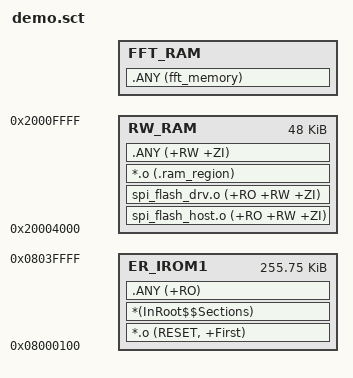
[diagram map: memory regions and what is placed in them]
; *************************************************************
; *** Scatter-Loading Description File generated by uVision ***
; *************************************************************



LR_IROM1 0x08000100 0x3FF00  {    ; load region size_region
  ER_IROM1 0x08000100 0x3FF00  {  ; load address = execution address
   *.o (RESET, +First)
   *(InRoot$$Sections)
   .ANY (+RO)
  }

  RW_RAM 0x20004000 0xc000{
    spi_flash_host.o (+RO +RW +ZI)
    spi_flash_drv.o  (+RO +RW +ZI)
    *.o              (.ram_region)
    .ANY             (+RW +ZI)
  }
  FFT_RAM AlignExpr(0x2000c000, 4) {
   .ANY (fft_memory)
  }
}
